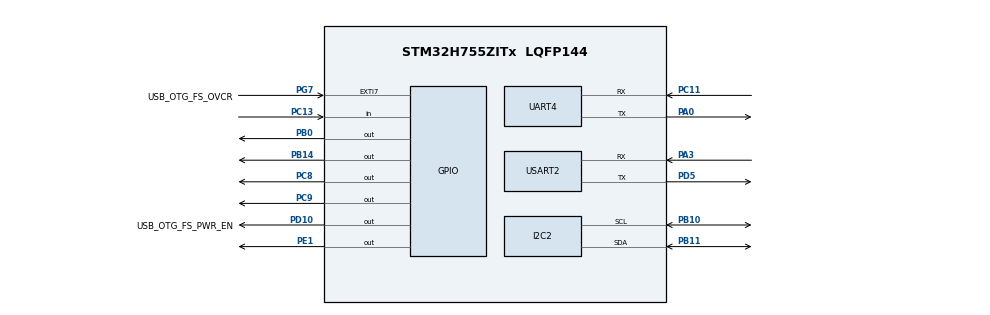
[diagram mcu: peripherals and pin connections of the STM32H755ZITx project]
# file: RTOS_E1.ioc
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CortexM4.IPs=FATFS_M4\:I,FREERTOS_M4\:I,IWDG2\:I,RCC,WWDG2\:I,DMA,BDMA,MDMA,NVIC2\:I,ETH,DEBUG,PDM2PCM_M4\:I,PWR,RESMGR_UTILITY,SYS_M4\:I,USB_DEVICE_M4\:I,USB_HOST_M4\:I,CORTEX_M4\:I,GPIO,OPENAMP_M4\:I,VREFBUF,NUCLEO-H755ZI-Q,USART3
CortexM4.Pins=PC8,PC9
CortexM7.IPs=FATFS_M7\:I,FREERTOS_M7\:I,IWDG1\:I,RCC\:I,WWDG1\:I,DMA\:I,BDMA\:I,MDMA\:I,NVIC1\:I,ETH\:I,USB_OTG_FS\:I,SYS\:I,CORTEX_M7\:I,DEBUG\:I,PDM2PCM_M7\:I,PWR\:I,RESMGR_UTILITY\:I,USB_DEVICE_M7\:I,USB_HOST_M7\:I,GPIO\:I,OPENAMP_M7\:I,VREFBUF\:I,I2C2\:I,NUCLEO-H755ZI-Q\:I,USART3\:I,UART4\:I,USART2\:I
I2C2.Timing=0x00303D5B
Mcu.Family=STM32H7
Mcu.Name=STM32H755ZITx
Mcu.Package=LQFP144
NUCLEO-H755ZI-Q.BUTTON=1
NUCLEO-H755ZI-Q.LD1=true
NUCLEO-H755ZI-Q.LD2=true
NUCLEO-H755ZI-Q.LD3=true
NUCLEO-H755ZI-Q.VCP=true
NVIC1.EXTI15_10_IRQn=true\:0\:0\:false\:false\:true\:false\:true\:true
NVIC1.PriorityGroup=NVIC_PRIORITYGROUP_4
NVIC2.PriorityGroup=NVIC_PRIORITYGROUP_4
PA0.Mode=Asynchronous
PA0.PinAttribute=CortexM7
PA0.Signal=UART4_TX
PA1.PinAttribute=CortexM7
PA1.Signal=ETH_REF_CLK
PA11.PinAttribute=CortexM7
PA11.Signal=USB_OTG_FS_DM
PA12.PinAttribute=CortexM7
PA12.Signal=USB_OTG_FS_DP
PA2.PinAttribute=CortexM7
PA2.Signal=ETH_MDIO
PA3.Mode=Asynchronous
PA3.PinAttribute=CortexM7
PA3.Signal=USART2_RX
PA7.PinAttribute=CortexM7
PA7.Signal=ETH_CRS_DV
PA8.PinAttribute=CortexM7
PA8.Signal=USB_OTG_FS_SOF
PA9.PinAttribute=CortexM7
PA9.Signal=USB_OTG_FS_VBUS
PB0.Signal=GPIO_Output
PB10.Mode=I2C
PB10.PinAttribute=CortexM7
PB10.Signal=I2C2_SCL
PB11.Mode=I2C
PB11.PinAttribute=CortexM7
PB11.Signal=I2C2_SDA
PB13.PinAttribute=CortexM7
PB13.Signal=ETH_TXD1
PB14.Signal=GPIO_Output
PB6.Signal=I2C1_SCL
PB7.Signal=I2C1_SDA
PC1.PinAttribute=CortexM7
PC1.Signal=ETH_MDC
PC11.Mode=Asynchronous
PC11.PinAttribute=CortexM7
PC11.Signal=UART4_RX
PC13.Signal=GPIO_Input
PC14-OSC32_IN\ (OSC32_IN).PinAttribute=Free
PC14-OSC32_IN\ (OSC32_IN).Signal=RCC_OSC32_IN
PC15-OSC32_OUT\ (OSC32_OUT).PinAttribute=Free
PC15-OSC32_OUT\ (OSC32_OUT).Signal=RCC_OSC32_OUT
PC4.PinAttribute=CortexM7
PC4.Signal=ETH_RXD0
PC5.PinAttribute=CortexM7
PC5.Signal=ETH_RXD1
PC8.PinAttribute=CortexM4
PC8.Signal=GPIO_Output
PC9.PinAttribute=CortexM4
PC9.Signal=GPIO_Output
PD10.GPIO_Label=USB_OTG_FS_PWR_EN
PD10.PinAttribute=Free
PD10.Signal=GPIO_Output
PD5.Mode=Asynchronous
PD5.PinAttribute=CortexM7
PD5.Signal=USART2_TX
PD8.Signal=USART3_TX
PD9.Signal=USART3_RX
PE1.Signal=GPIO_Output
PG11.PinAttribute=CortexM7
PG11.Signal=ETH_TX_EN
PG13.PinAttribute=CortexM7
PG13.Signal=ETH_TXD0
PG7.GPIO_Label=USB_OTG_FS_OVCR
PG7.PinAttribute=Free
PG7.Signal=GPXTI7
PH0-OSC_IN\ (PH0).Mode=HSE-External-Oscillator
PH0-OSC_IN\ (PH0).PinAttribute=Free
PH0-OSC_IN\ (PH0).Signal=RCC_OSC_IN
PH1-OSC_OUT\ (PH1).Mode=HSE-External-Oscillator
PH1-OSC_OUT\ (PH1).PinAttribute=Free
PH1-OSC_OUT\ (PH1).Signal=RCC_OSC_OUT
ProjectManager.HeapSize=M4-0x200,M7-0x200
ProjectManager.StackSize=M4-0x400,M7-0x400
ProjectManager.TargetToolchain=STM32CubeIDE
RCC.ADCFreq_Value=50390625
RCC.APB1Freq_Value=16000000
RCC.APB2Freq_Value=32000000
RCC.APB3Freq_Value=32000000
RCC.APB4Freq_Value=32000000
RCC.CortexFreq_Value=32000000
RCC.D2PPRE1=RCC_APB1_DIV2
RCC.DIVM1=5
RCC.DIVN1=48
RCC.DIVQ1=5
RCC.HCLKFreq_Value=32000000
RCC.HSE_VALUE=25000000
RCC.HSIDiv=RCC_PLLSAIDIVR_2
RCC.PLLSourceVirtual=RCC_PLLSOURCE_HSE
RCC.SYSCLKFreq_VALUE=32000000
RCC.SupplySource=PWR_DIRECT_SMPS_SUPPLY
RCC.USART234578CLockSelection=RCC_USART234578CLKSOURCE_HSI
RCC.USBFreq_Value=48000000
USART2.VirtualMode-Asynchronous=VM_ASYNC
VP_NUCLEO-H755ZI-Q_VS_BSP_COMMON.Mode=COMMON
VP_SYS_M4_VS_Systick.Mode=SysTick
board=NUCLEO-H755ZI-Q

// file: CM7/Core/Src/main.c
/* USER CODE BEGIN Header */
/**
  ******************************************************************************
  * @file           : main.c
  * @brief          : Main program body
  ******************************************************************************
  * @attention
  *
  * Copyright (c) 2024 STMicroelectronics.
  * All rights reserved.
  *
  * This software is licensed under terms that can be found in the LICENSE file
  * in the root directory of this software component.
  * If no LICENSE file comes with this software, it is provided AS-IS.
  *
  ******************************************************************************
  */
/* USER CODE END Header */
#include "main.h"

/* USER CODE BEGIN Includes */
#include <string.h>
/* USER CODE END Includes */

/* USER CODE BEGIN PD */

#ifndef HSEM_ID_0
#define HSEM_ID_0 (0U) /* HW semaphore 0*/
#endif

/* USER CODE END PD */

COM_InitTypeDef BspCOMInit;

I2C_HandleTypeDef hi2c2;

UART_HandleTypeDef huart4;
UART_HandleTypeDef huart2;

void SystemClock_Config(void);
static void MX_GPIO_Init(void);
static void MX_I2C2_Init(void);
static void MX_UART4_Init(void);
static void MX_USART2_UART_Init(void);

int main(void)
{

/* USER CODE BEGIN Boot_Mode_Sequence_0 */
  int32_t timeout;
/* USER CODE END Boot_Mode_Sequence_0 */

/* USER CODE BEGIN Boot_Mode_Sequence_1 */
  /* Wait until CPU2 boots and enters in stop mode or timeout*/
  timeout = 0xFFFF;
  while((__HAL_RCC_GET_FLAG(RCC_FLAG_D2CKRDY) != RESET) && (timeout-- > 0));
  if ( timeout < 0 )
  {
  Error_Handler();
  }
/* USER CODE END Boot_Mode_Sequence_1 */
  /* MCU Configuration--------------------------------------------------------*/

  /* Reset of all peripherals, Initializes the Flash interface and the Systick. */
  HAL_Init();

  /* Configure the system clock */
  SystemClock_Config();
/* USER CODE BEGIN Boot_Mode_Sequence_2 */
/* When system initialization is finished, Cortex-M7 will release Cortex-M4 by means of
HSEM notification */
/*HW semaphore Clock enable*/
__HAL_RCC_HSEM_CLK_ENABLE();
/*Take HSEM */
HAL_HSEM_FastTake(HSEM_ID_0);
/*Release HSEM in order to notify the CPU2(CM4)*/
HAL_HSEM_Release(HSEM_ID_0,0);
/* wait until CPU2 wakes up from stop mode */
timeout = 0xFFFF;
while((__HAL_RCC_GET_FLAG(RCC_FLAG_D2CKRDY) == RESET) && (timeout-- > 0));
if ( timeout < 0 )
{
Error_Handler();
}
/* USER CODE END Boot_Mode_Sequence_2 */

  /* Initialize all configured peripherals */
  MX_GPIO_Init();
  MX_I2C2_Init();
  MX_UART4_Init();
  MX_USART2_UART_Init();

  /* Initialize leds */
  BSP_LED_Init(LED_GREEN);
  BSP_LED_Init(LED_YELLOW);
  BSP_LED_Init(LED_RED);

  /* Initialize USER push-button, will be used to trigger an interrupt each time it's pressed.*/
  BSP_PB_Init(BUTTON_USER, BUTTON_MODE_EXTI);

  /* Initialize COM1 port (115200, 8 bits (7-bit data + 1 stop bit), no parity */
  BspCOMInit.BaudRate   = 115200;
  BspCOMInit.WordLength = COM_WORDLENGTH_8B;
  BspCOMInit.StopBits   = COM_STOPBITS_1;
  BspCOMInit.Parity     = COM_PARITY_NONE;
  BspCOMInit.HwFlowCtl  = COM_HWCONTROL_NONE;
  if (BSP_COM_Init(COM1, &BspCOMInit) != BSP_ERROR_NONE)
  {
    Error_Handler();
  }

  /* Infinite loop */
  /* USER CODE BEGIN WHILE */
  char msg[20] = "ABC\n\r";
  char msg1[20] = "ABCdef\n\r";
  while (1)
  {

    /* USER CODE END WHILE */

    /* USER CODE BEGIN 3 */
	/*// LED ON
	HAL_GPIO_WritePin(GPIOC, GPIO_PIN_8, GPIO_PIN_SET);
	HAL_Delay(500);
	// LED OFF
	HAL_GPIO_WritePin(GPIOC, GPIO_PIN_8, GPIO_PIN_RESET);
	HAL_Delay(500);*/
	HAL_UART_Transmit(&huart4, (uint8_t*)msg, strlen(msg), HAL_MAX_DELAY); //&huart2
	HAL_UART_Transmit(&huart2, (uint8_t*)msg1, strlen(msg1), HAL_MAX_DELAY);
	//printf("stm32");
	HAL_Delay(500);
	/* Turn LED1 off */
	BSP_LED_Off(LED_GREEN);
	HAL_Delay(500);
	/* Turn LED1 on */
	BSP_LED_On(LED_GREEN);
  }
  /* USER CODE END 3 */
}

void SystemClock_Config(void)
{
  RCC_OscInitTypeDef RCC_OscInitStruct = {0};
  RCC_ClkInitTypeDef RCC_ClkInitStruct = {0};

  /** Supply configuration update enable
  */
  HAL_PWREx_ConfigSupply(PWR_DIRECT_SMPS_SUPPLY);

  /** Configure the main internal regulator output voltage
  */
  __HAL_PWR_VOLTAGESCALING_CONFIG(PWR_REGULATOR_VOLTAGE_SCALE3);

  while(!__HAL_PWR_GET_FLAG(PWR_FLAG_VOSRDY)) {}

  /** Initializes the RCC Oscillators according to the specified parameters
  * in the RCC_OscInitTypeDef structure.
  */
  RCC_OscInitStruct.OscillatorType = RCC_OSCILLATORTYPE_HSI;
  RCC_OscInitStruct.HSIState = RCC_HSI_DIV2;
  RCC_OscInitStruct.HSICalibrationValue = RCC_HSICALIBRATION_DEFAULT;
  RCC_OscInitStruct.PLL.PLLState = RCC_PLL_NONE;
  if (HAL_RCC_OscConfig(&RCC_OscInitStruct) != HAL_OK)
  {
    Error_Handler();
  }

  /** Initializes the CPU, AHB and APB buses clocks
  */
  RCC_ClkInitStruct.ClockType = RCC_CLOCKTYPE_HCLK|RCC_CLOCKTYPE_SYSCLK
                              |RCC_CLOCKTYPE_PCLK1|RCC_CLOCKTYPE_PCLK2
                              |RCC_CLOCKTYPE_D3PCLK1|RCC_CLOCKTYPE_D1PCLK1;
  RCC_ClkInitStruct.SYSCLKSource = RCC_SYSCLKSOURCE_HSI;
  RCC_ClkInitStruct.SYSCLKDivider = RCC_SYSCLK_DIV1;
  RCC_ClkInitStruct.AHBCLKDivider = RCC_HCLK_DIV1;
  RCC_ClkInitStruct.APB3CLKDivider = RCC_APB3_DIV1;
  RCC_ClkInitStruct.APB1CLKDivider = RCC_APB1_DIV2;
  RCC_ClkInitStruct.APB2CLKDivider = RCC_APB2_DIV1;
  RCC_ClkInitStruct.APB4CLKDivider = RCC_APB4_DIV1;

  if (HAL_RCC_ClockConfig(&RCC_ClkInitStruct, FLASH_LATENCY_0) != HAL_OK)
  {
    Error_Handler();
  }
}

static void MX_I2C2_Init(void)
{

  hi2c2.Instance = I2C2;
  hi2c2.Init.Timing = 0x00303D5B;
  hi2c2.Init.OwnAddress1 = 0;
  hi2c2.Init.AddressingMode = I2C_ADDRESSINGMODE_7BIT;
  hi2c2.Init.DualAddressMode = I2C_DUALADDRESS_DISABLE;
  hi2c2.Init.OwnAddress2 = 0;
  hi2c2.Init.OwnAddress2Masks = I2C_OA2_NOMASK;
  hi2c2.Init.GeneralCallMode = I2C_GENERALCALL_DISABLE;
  hi2c2.Init.NoStretchMode = I2C_NOSTRETCH_DISABLE;
  if (HAL_I2C_Init(&hi2c2) != HAL_OK)
  {
    Error_Handler();
  }

  /** Configure Analogue filter
  */
  if (HAL_I2CEx_ConfigAnalogFilter(&hi2c2, I2C_ANALOGFILTER_ENABLE) != HAL_OK)
  {
    Error_Handler();
  }

  /** Configure Digital filter
  */
  if (HAL_I2CEx_ConfigDigitalFilter(&hi2c2, 0) != HAL_OK)
  {
    Error_Handler();
  }

}

static void MX_UART4_Init(void)
{

  huart4.Instance = UART4;
  huart4.Init.BaudRate = 115200;
  huart4.Init.WordLength = UART_WORDLENGTH_8B;
  huart4.Init.StopBits = UART_STOPBITS_1;
  huart4.Init.Parity = UART_PARITY_NONE;
  huart4.Init.Mode = UART_MODE_TX_RX;
  huart4.Init.HwFlowCtl = UART_HWCONTROL_NONE;
  huart4.Init.OverSampling = UART_OVERSAMPLING_16;
  huart4.Init.OneBitSampling = UART_ONE_BIT_SAMPLE_DISABLE;
  huart4.Init.ClockPrescaler = UART_PRESCALER_DIV1;
  huart4.AdvancedInit.AdvFeatureInit = UART_ADVFEATURE_NO_INIT;
  if (HAL_UART_Init(&huart4) != HAL_OK)
  {
    Error_Handler();
  }
  if (HAL_UARTEx_SetTxFifoThreshold(&huart4, UART_TXFIFO_THRESHOLD_1_8) != HAL_OK)
  {
    Error_Handler();
  }
  if (HAL_UARTEx_SetRxFifoThreshold(&huart4, UART_RXFIFO_THRESHOLD_1_8) != HAL_OK)
  {
    Error_Handler();
  }
  if (HAL_UARTEx_DisableFifoMode(&huart4) != HAL_OK)
  {
    Error_Handler();
  }

}

static void MX_USART2_UART_Init(void)
{

  huart2.Instance = USART2;
  huart2.Init.BaudRate = 115200;
  huart2.Init.WordLength = UART_WORDLENGTH_8B;
  huart2.Init.StopBits = UART_STOPBITS_1;
  huart2.Init.Parity = UART_PARITY_NONE;
  huart2.Init.Mode = UART_MODE_TX_RX;
  huart2.Init.HwFlowCtl = UART_HWCONTROL_NONE;
  huart2.Init.OverSampling = UART_OVERSAMPLING_16;
  huart2.Init.OneBitSampling = UART_ONE_BIT_SAMPLE_DISABLE;
  huart2.Init.ClockPrescaler = UART_PRESCALER_DIV1;
  huart2.AdvancedInit.AdvFeatureInit = UART_ADVFEATURE_NO_INIT;
  if (HAL_UART_Init(&huart2) != HAL_OK)
  {
    Error_Handler();
  }
  if (HAL_UARTEx_SetTxFifoThreshold(&huart2, UART_TXFIFO_THRESHOLD_1_8) != HAL_OK)
  {
    Error_Handler();
  }
  if (HAL_UARTEx_SetRxFifoThreshold(&huart2, UART_RXFIFO_THRESHOLD_1_8) != HAL_OK)
  {
    Error_Handler();
  }
  if (HAL_UARTEx_DisableFifoMode(&huart2) != HAL_OK)
  {
    Error_Handler();
  }

}

static void MX_GPIO_Init(void)
{
  GPIO_InitTypeDef GPIO_InitStruct = {0};

  /* GPIO Ports Clock Enable */
  __HAL_RCC_GPIOC_CLK_ENABLE();
  __HAL_RCC_GPIOA_CLK_ENABLE();
  __HAL_RCC_GPIOB_CLK_ENABLE();
  __HAL_RCC_GPIOD_CLK_ENABLE();
  __HAL_RCC_GPIOG_CLK_ENABLE();

  /*Configure GPIO pins : PC1 PC4 PC5 */
  GPIO_InitStruct.Pin = GPIO_PIN_1|GPIO_PIN_4|GPIO_PIN_5;
  GPIO_InitStruct.Mode = GPIO_MODE_AF_PP;
  GPIO_InitStruct.Pull = GPIO_NOPULL;
  GPIO_InitStruct.Speed = GPIO_SPEED_FREQ_LOW;
  GPIO_InitStruct.Alternate = GPIO_AF11_ETH;
  HAL_GPIO_Init(GPIOC, &GPIO_InitStruct);

  /*Configure GPIO pins : PA1 PA2 PA7 */
  GPIO_InitStruct.Pin = GPIO_PIN_1|GPIO_PIN_2|GPIO_PIN_7;
  GPIO_InitStruct.Mode = GPIO_MODE_AF_PP;
  GPIO_InitStruct.Pull = GPIO_NOPULL;
  GPIO_InitStruct.Speed = GPIO_SPEED_FREQ_LOW;
  GPIO_InitStruct.Alternate = GPIO_AF11_ETH;
  HAL_GPIO_Init(GPIOA, &GPIO_InitStruct);

  /*Configure GPIO pin : PB13 */
  GPIO_InitStruct.Pin = GPIO_PIN_13;
  GPIO_InitStruct.Mode = GPIO_MODE_AF_PP;
  GPIO_InitStruct.Pull = GPIO_NOPULL;
  GPIO_InitStruct.Speed = GPIO_SPEED_FREQ_LOW;
  GPIO_InitStruct.Alternate = GPIO_AF11_ETH;
  HAL_GPIO_Init(GPIOB, &GPIO_InitStruct);

  /*Configure GPIO pins : PA8 PA11 PA12 */
  GPIO_InitStruct.Pin = GPIO_PIN_8|GPIO_PIN_11|GPIO_PIN_12;
  GPIO_InitStruct.Mode = GPIO_MODE_AF_PP;
  GPIO_InitStruct.Pull = GPIO_NOPULL;
  GPIO_InitStruct.Speed = GPIO_SPEED_FREQ_LOW;
  GPIO_InitStruct.Alternate = GPIO_AF10_OTG1_FS;
  HAL_GPIO_Init(GPIOA, &GPIO_InitStruct);

  /*Configure GPIO pins : PG11 PG13 */
  GPIO_InitStruct.Pin = GPIO_PIN_11|GPIO_PIN_13;
  GPIO_InitStruct.Mode = GPIO_MODE_AF_PP;
  GPIO_InitStruct.Pull = GPIO_NOPULL;
  GPIO_InitStruct.Speed = GPIO_SPEED_FREQ_LOW;
  GPIO_InitStruct.Alternate = GPIO_AF11_ETH;
  HAL_GPIO_Init(GPIOG, &GPIO_InitStruct);

}

void Error_Handler(void)
{
  __disable_irq();
  while (1)
  {
  }
}
